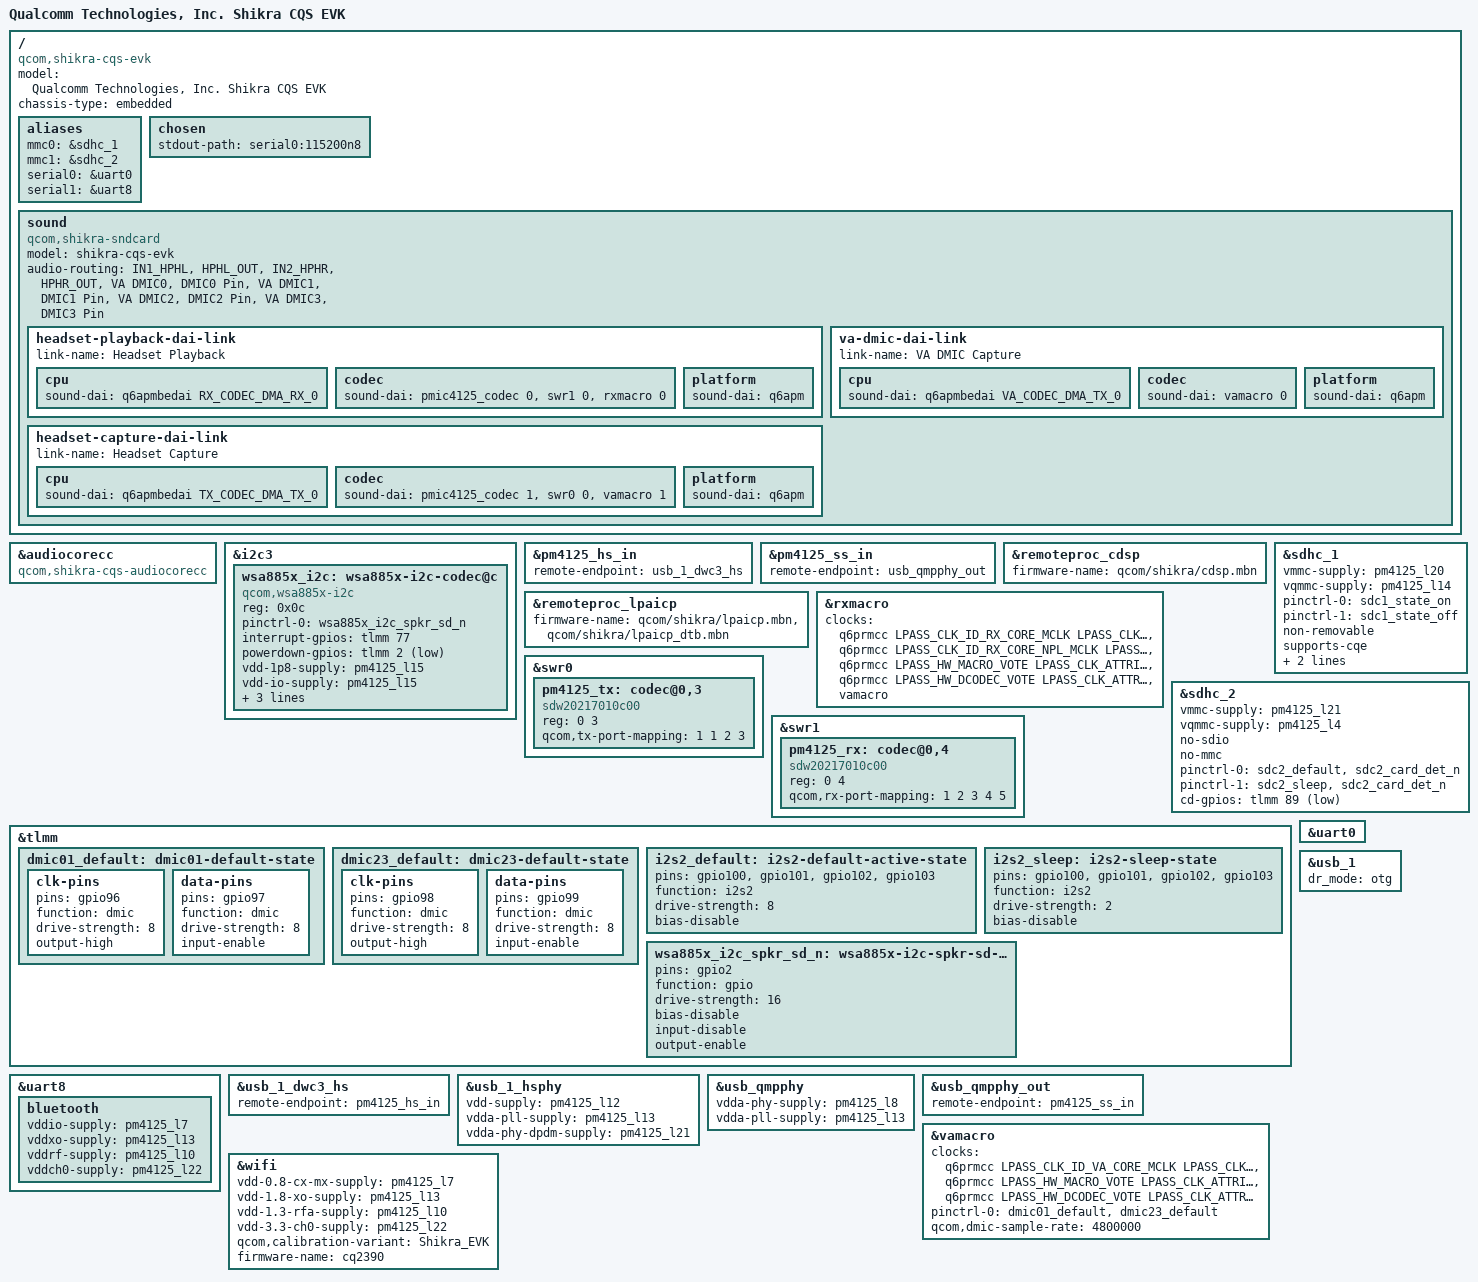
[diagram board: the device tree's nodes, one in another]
// SPDX-License-Identifier: BSD-3-Clause
/*
 * Copyright (c) Qualcomm Technologies, Inc. and/or its subsidiaries.
 */

/dts-v1/;

#include "shikra-cqs-som.dtsi"
#include "shikra-evk.dtsi"
#include <dt-bindings/gpio/gpio.h>

/ {
	model = "Qualcomm Technologies, Inc. Shikra CQS EVK";
	compatible = "qcom,shikra-cqs-evk", "qcom,shikra-cqs-som", "qcom,shikra";
	chassis-type = "embedded";

	aliases {
		mmc0 = &sdhc_1;
		mmc1 = &sdhc_2; /* SDC2 SD card slot */
		serial0 = &uart0;
		serial1 = &uart8;
	};

	chosen {
		stdout-path = "serial0:115200n8";
	};

	sound {
		compatible = "qcom,shikra-sndcard";
		model = "shikra-cqs-evk";

		audio-routing = "IN1_HPHL", "HPHL_OUT",
				"IN2_HPHR", "HPHR_OUT",
				"VA DMIC0", "DMIC0 Pin",
				"VA DMIC1", "DMIC1 Pin",
				"VA DMIC2", "DMIC2 Pin",
				"VA DMIC3", "DMIC3 Pin";

		headset-playback-dai-link {
			link-name = "Headset Playback";

			cpu {
				sound-dai = <&q6apmbedai RX_CODEC_DMA_RX_0>;
			};

			codec {
				sound-dai = <&pmic4125_codec 0>,
					    <&swr1 0>,
					    <&rxmacro 0>;
			};

			platform {
				sound-dai = <&q6apm>;
			};
		};

		headset-capture-dai-link {
			link-name = "Headset Capture";

			cpu {
				sound-dai = <&q6apmbedai TX_CODEC_DMA_TX_0>;
			};

			codec {
				sound-dai = <&pmic4125_codec 1>,
					    <&swr0 0>,
					    <&vamacro 1>;
			};

			platform {
				sound-dai = <&q6apm>;
			};
		};

		va-dmic-dai-link {
			link-name = "VA DMIC Capture";

			cpu {
				sound-dai = <&q6apmbedai VA_CODEC_DMA_TX_0>;
			};

			codec {
				sound-dai = <&vamacro 0>;
			};

			platform {
				sound-dai = <&q6apm>;
			};
		};
	};

};

&audiocorecc {
	compatible = "qcom,shikra-cqs-audiocorecc";
};

&i2c3 {
	status = "okay";

	wsa885x_i2c: wsa885x-i2c-codec@c {
		compatible = "qcom,wsa885x-i2c";
		reg = <0x0c>;

		pinctrl-names = "default";
		pinctrl-0 = <&wsa885x_i2c_spkr_sd_n>;

		interrupt-gpios = <&tlmm 77 GPIO_ACTIVE_HIGH>;
		powerdown-gpios = <&tlmm 2 GPIO_ACTIVE_LOW>;
		vdd-1p8-supply = <&pm4125_l15>;
		vdd-io-supply = <&pm4125_l15>;
		qcom,battery_config = <2>;

		wsa885x-init-table =
			<0x8470 0x2
			0x8470 0x0
			0x8470 0x1
			0x0004 0x1
			0x8602 0x60
			0x8622 0x60
			0x8458 0x79
			0x810B 0xD9
			0x8111 0xD9
			0x813C 0x08
			0x8102 0x04
			0x811C 0x29
			0x811D 0x40
			0x8129 0x40
			0x811A 0x80
			0x8126 0x80
			0x8103 0x6
			0x80CA 0x85
			0x80CB 0xE
			0x80CC 0xC
			0x80D0 0x80
			0x80BA 0xC0
			0x841C 0x4E
			0x8435 0x47
			0x86CE 0x09
			0x8667 0x34
			0x800D 0x08>;

		#sound-dai-cells = <0>;
	};
};

&pm4125_hs_in {
	remote-endpoint = <&usb_1_dwc3_hs>;
};

&pm4125_ss_in {
	remote-endpoint = <&usb_qmpphy_out>;
};

&remoteproc_cdsp {
	firmware-name = "qcom/shikra/cdsp.mbn";

	status = "okay";
};

&remoteproc_lpaicp {
	firmware-name = "qcom/shikra/lpaicp.mbn",
			"qcom/shikra/lpaicp_dtb.mbn";

	status = "okay";
};

&rxmacro {
	clocks = <&q6prmcc LPASS_CLK_ID_RX_CORE_MCLK LPASS_CLK_ATTRIBUTE_COUPLE_NO>,
		 <&q6prmcc LPASS_CLK_ID_RX_CORE_NPL_MCLK LPASS_CLK_ATTRIBUTE_COUPLE_NO>,
		 <&q6prmcc LPASS_HW_MACRO_VOTE LPASS_CLK_ATTRIBUTE_COUPLE_NO>,
		 <&q6prmcc LPASS_HW_DCODEC_VOTE LPASS_CLK_ATTRIBUTE_COUPLE_NO>,
		 <&vamacro>;
	clock-names = "mclk",
		      "npl",
		      "macro",
		      "dcodec",
		      "fsgen";

	status = "okay";
};

&sdhc_1 {
	vmmc-supply = <&pm4125_l20>;
	vqmmc-supply = <&pm4125_l14>;

	pinctrl-0 = <&sdc1_state_on>;
	pinctrl-1 = <&sdc1_state_off>;
	pinctrl-names = "default", "sleep";

	non-removable;
	supports-cqe;
	no-sdio;
	no-sd;

	status = "okay";
};

&sdhc_2 {
	vmmc-supply = <&pm4125_l21>;
	vqmmc-supply = <&pm4125_l4>;

	no-sdio;
	no-mmc;

	pinctrl-0 = <&sdc2_default &sdc2_card_det_n>;
	pinctrl-1 = <&sdc2_sleep &sdc2_card_det_n>;
	pinctrl-names = "default", "sleep";

	cd-gpios = <&tlmm 89 GPIO_ACTIVE_LOW>;

	status = "okay";
};

&swr0 {
	status = "okay";

	pm4125_tx: codec@0,3 {
		compatible = "sdw20217010c00";
		reg = <0 3>;
		qcom,tx-port-mapping = <1 1 2 3>;
	};
};

&swr1 {
	status = "okay";

	pm4125_rx: codec@0,4 {
		compatible = "sdw20217010c00";
		reg = <0 4>;
		qcom,rx-port-mapping = <1 2 3 4 5>;
	};
};

&tlmm {
	dmic01_default: dmic01-default-state {
		clk-pins {
			pins = "gpio96";
			function = "dmic";
			drive-strength = <8>;
			output-high;
		};

		data-pins {
			pins = "gpio97";
			function = "dmic";
			drive-strength = <8>;
			input-enable;
		};
	};

	dmic23_default: dmic23-default-state {
		clk-pins {
			pins = "gpio98";
			function = "dmic";
			drive-strength = <8>;
			output-high;
		};

		data-pins {
			pins = "gpio99";
			function = "dmic";
			drive-strength = <8>;
			input-enable;
		};
	};

	i2s2_default: i2s2-default-active-state {
		pins = "gpio100", "gpio101", "gpio102", "gpio103";
		function = "i2s2";
		drive-strength = <8>;
		bias-disable;
	};

	i2s2_sleep: i2s2-sleep-state {
		pins = "gpio100", "gpio101", "gpio102", "gpio103";
		function = "i2s2";
		drive-strength = <2>;
		bias-disable;
	};

	wsa885x_i2c_spkr_sd_n: wsa885x-i2c-spkr-sd-n-active-state {
		pins = "gpio2";
		function = "gpio";
		drive-strength = <16>;
		bias-disable;
		input-disable;
		output-enable;
	};
};

&uart0 {
	status = "okay";
};

&uart8 {
	status = "okay";

	bluetooth {
		vddio-supply = <&pm4125_l7>;
		vddxo-supply = <&pm4125_l13>;
		vddrf-supply = <&pm4125_l10>;
		vddch0-supply = <&pm4125_l22>;
	};
};

&usb_1 {
	dr_mode = "otg";

	status = "okay";
};

&usb_1_dwc3_hs {
	remote-endpoint = <&pm4125_hs_in>;
};

&usb_1_hsphy {
	vdd-supply = <&pm4125_l12>;
	vdda-pll-supply = <&pm4125_l13>;
	vdda-phy-dpdm-supply = <&pm4125_l21>;

	status = "okay";
};

&usb_qmpphy {
	vdda-phy-supply = <&pm4125_l8>;
	vdda-pll-supply = <&pm4125_l13>;

	status = "okay";
};

&usb_qmpphy_out {
	remote-endpoint = <&pm4125_ss_in>;
};

&vamacro {
	clocks = <&q6prmcc LPASS_CLK_ID_VA_CORE_MCLK LPASS_CLK_ATTRIBUTE_COUPLE_NO>,
		 <&q6prmcc LPASS_HW_MACRO_VOTE LPASS_CLK_ATTRIBUTE_COUPLE_NO>,
		 <&q6prmcc LPASS_HW_DCODEC_VOTE LPASS_CLK_ATTRIBUTE_COUPLE_NO>;
	clock-names = "mclk",
		      "macro",
		      "dcodec";
	pinctrl-0 = <&dmic01_default>, <&dmic23_default>;
	pinctrl-names = "default";

	qcom,dmic-sample-rate = <4800000>;
	status = "okay";
};

&wifi {
	vdd-0.8-cx-mx-supply = <&pm4125_l7>;
	vdd-1.8-xo-supply = <&pm4125_l13>;
	vdd-1.3-rfa-supply = <&pm4125_l10>;
	vdd-3.3-ch0-supply = <&pm4125_l22>;
	qcom,calibration-variant = "Shikra_EVK";
	firmware-name = "cq2390";

	status = "okay";
};
